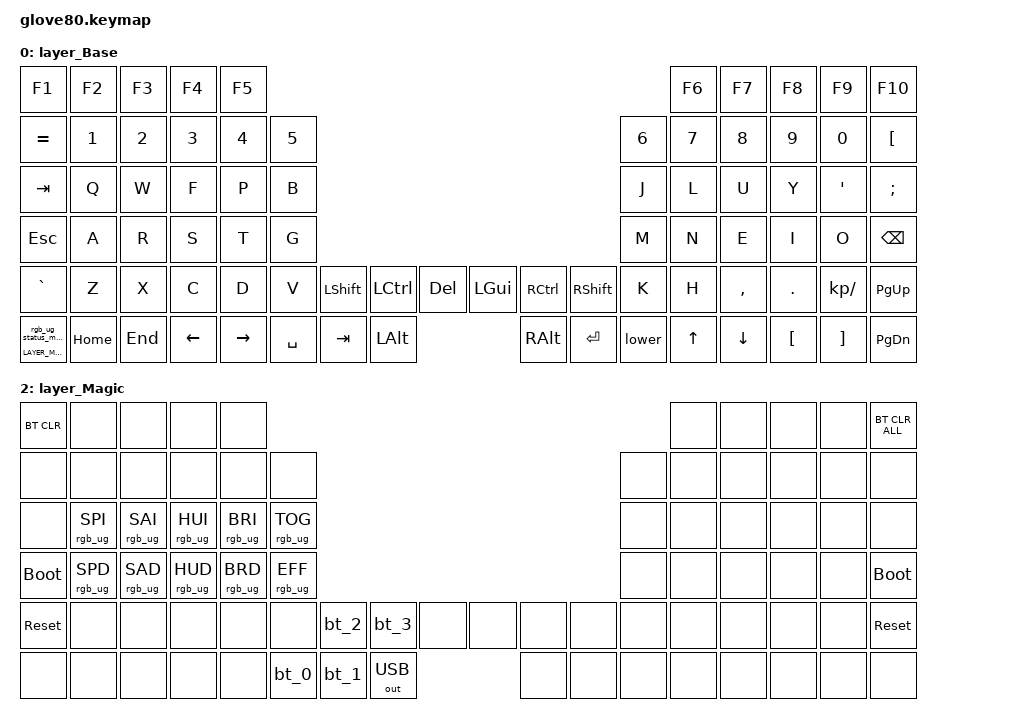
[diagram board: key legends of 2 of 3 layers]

/*
 * Copyright (c) 2020 The ZMK Contributors
 * Copyright (c) 2023 Innaworks Development Limited, trading as MoErgo
 *
 * SPDX-License-Identifier: MIT
 */


/* THIS FILE WAS GENERATED BY GLOVE80 LAYOUT EDITOR
 *
 * This file was generated automatically. You may or may not want to
 * edit it directly.
 */

#include <behaviors.dtsi>
/* Include all behavior includes needed */
#include <dt-bindings/zmk/outputs.h>
#include <dt-bindings/zmk/keys.h>
#include <dt-bindings/zmk/bt.h>
#include <dt-bindings/zmk/rgb.h>

/* Automatically generated layer name #define */
#define LAYER_Base 0
#define LAYER_Lower 1
#define LAYER_Magic 2

/* To deal with the situation where there is no Lower layer, to keep &lower happy */
#ifndef LAYER_Lower
#define LAYER_Lower 0
#endif

/* Custom Device-tree */



/* Glove80 system behavior & macros */
/ {
    behaviors {
        // For the "layer" key, it'd nice to be able to use it as either a shift or a toggle.
        // Configure it as a tap dance, so the first tap (or hold) is a &mo and the second tap is a &to
        lower: lower {
            compatible = "zmk,behavior-tap-dance";
            label = "LAYER_TAP_DANCE";
            #binding-cells = <0>;
            tapping-term-ms = <200>;
            bindings = <&mo LAYER_Lower>, <&to LAYER_Lower>;
        };
    };
};

/ {
    macros {
        rgb_ug_status_macro: rgb_ug_status_macro {
            label = "RGB_UG_STATUS";
            compatible = "zmk,behavior-macro";
            #binding-cells = <0>;
            bindings
                = <&rgb_ug RGB_STATUS>;
        };
    };
};


/ {
#ifdef BT_DISC_CMD
    behaviors {
        bt_0: bt_0 {
            compatible = "zmk,behavior-tap-dance";
            label = "BT_0";
            #binding-cells = <0>;
            tapping-term-ms = <200>;
            bindings = <&bt_select_0>, <&bt BT_DISC 0>;
        };
        bt_1: bt_1 {
            compatible = "zmk,behavior-tap-dance";
            label = "BT_1";
            #binding-cells = <0>;
            tapping-term-ms = <200>;
            bindings = <&bt_select_1>, <&bt BT_DISC 1>;
        };
        bt_2: bt_2 {
            compatible = "zmk,behavior-tap-dance";
            label = "BT_2";
            #binding-cells = <0>;
            tapping-term-ms = <200>;
            bindings = <&bt_select_2>, <&bt BT_DISC 2>;
        };
        bt_3: bt_3 {
            compatible = "zmk,behavior-tap-dance";
            label = "BT_3";
            #binding-cells = <0>;
            tapping-term-ms = <200>;
            bindings = <&bt_select_3>, <&bt BT_DISC 3>;
        };
    };
    macros {
        bt_select_0: bt_select_0 {
            label = "BT_SELECT_0";
            compatible = "zmk,behavior-macro";
            #binding-cells = <0>;
            bindings
                = <&out OUT_BLE>,
                  <&bt BT_SEL 0>;
        };
        bt_select_1: bt_select_1 {
            label = "BT_SELECT_1";
            compatible = "zmk,behavior-macro";
            #binding-cells = <0>;
            bindings
                = <&out OUT_BLE>,
                  <&bt BT_SEL 1>;
        };
        bt_select_2: bt_select_2 {
            label = "BT_SELECT_2";
            compatible = "zmk,behavior-macro";
            #binding-cells = <0>;
            bindings
                = <&out OUT_BLE>,
                  <&bt BT_SEL 2>;
        };
        bt_select_3: bt_select_3 {
            label = "BT_SELECT_3";
            compatible = "zmk,behavior-macro";
            #binding-cells = <0>;
            bindings
                = <&out OUT_BLE>,
                  <&bt BT_SEL 3>;
        };
    };
#else
    macros {
        bt_0: bt_0 {
            label = "BT_0";
            compatible = "zmk,behavior-macro";
            #binding-cells = <0>;
            bindings
                = <&out OUT_BLE>,
                  <&bt BT_SEL 0>;
        };
        bt_1: bt_1 {
            label = "BT_1";
            compatible = "zmk,behavior-macro";
            #binding-cells = <0>;
            bindings
                = <&out OUT_BLE>,
                  <&bt BT_SEL 1>;
        };
        bt_2: bt_2 {
            label = "BT_2";
            compatible = "zmk,behavior-macro";
            #binding-cells = <0>;
            bindings
                = <&out OUT_BLE>,
                  <&bt BT_SEL 2>;
        };
        bt_3: bt_3 {
            label = "BT_3";
            compatible = "zmk,behavior-macro";
            #binding-cells = <0>;
            bindings
                = <&out OUT_BLE>,
                  <&bt BT_SEL 3>;
        };
    };
#endif
};

/ {
    behaviors {
        magic: magic {
            compatible = "zmk,behavior-hold-tap";
            label = "MAGIC_HOLD_TAP";
            #binding-cells = <2>;
            flavor = "tap-preferred";
            tapping-term-ms = <200>;
            bindings = <&mo>, <&rgb_ug_status_macro>;
        };
    };
};

/* #define for key positions */
#define POS_LH_T1 52
#define POS_LH_T2 53
#define POS_LH_T3 54
#define POS_LH_T4 69
#define POS_LH_T5 70
#define POS_LH_T6 71
#define POS_LH_C1R2 15
#define POS_LH_C1R3 27
#define POS_LH_C1R4 39
#define POS_LH_C1R5 51
#define POS_LH_C2R1 4
#define POS_LH_C2R2 14
#define POS_LH_C2R3 26
#define POS_LH_C2R4 38
#define POS_LH_C2R5 50
#define POS_LH_C2R6 68
#define POS_LH_C3R1 3
#define POS_LH_C3R2 13
#define POS_LH_C3R3 25
#define POS_LH_C3R4 37
#define POS_LH_C3R5 49
#define POS_LH_C3R6 67
#define POS_LH_C4R1 2
#define POS_LH_C4R2 12
#define POS_LH_C4R3 24
#define POS_LH_C4R4 36
#define POS_LH_C4R5 48
#define POS_LH_C4R6 66
#define POS_LH_C5R1 1
#define POS_LH_C5R2 11
#define POS_LH_C5R3 23
#define POS_LH_C5R4 35
#define POS_LH_C5R5 47
#define POS_LH_C5R6 65
#define POS_LH_C6R1 0
#define POS_LH_C6R2 10
#define POS_LH_C6R3 22
#define POS_LH_C6R4 34
#define POS_LH_C6R5 46
#define POS_LH_C6R6 64
#define POS_RH_T1 57
#define POS_RH_T2 56
#define POS_RH_T3 55
#define POS_RH_T4 74
#define POS_RH_T5 73
#define POS_RH_T6 72
#define POS_RH_C1R2 16
#define POS_RH_C1R3 28
#define POS_RH_C1R4 40
#define POS_RH_C1R5 58
#define POS_RH_C2R1 5
#define POS_RH_C2R2 17
#define POS_RH_C2R3 29
#define POS_RH_C2R4 41
#define POS_RH_C2R5 59
#define POS_RH_C2R6 75
#define POS_RH_C3R1 6
#define POS_RH_C3R2 18
#define POS_RH_C3R3 30
#define POS_RH_C3R4 42
#define POS_RH_C3R5 60
#define POS_RH_C3R6 76
#define POS_RH_C4R1 7
#define POS_RH_C4R2 19
#define POS_RH_C4R3 31
#define POS_RH_C4R4 43
#define POS_RH_C4R5 61
#define POS_RH_C4R6 77
#define POS_RH_C5R1 8
#define POS_RH_C5R2 20
#define POS_RH_C5R3 32
#define POS_RH_C5R4 44
#define POS_RH_C5R5 62
#define POS_RH_C5R6 78
#define POS_RH_C6R1 9
#define POS_RH_C6R2 21
#define POS_RH_C6R3 33
#define POS_RH_C6R4 45
#define POS_RH_C6R5 63
#define POS_RH_C6R6 79


/* Special characters accessed with Shift */
#define SW_EXCL &kp LS(N1)          // Maps to `!` on Swedish layout (Shift + 1)
#define SW_AT &kp LS(N2)            // Maps to `@` on Swedish layout (Shift + 2)
#define SW_HASH &kp LS(N3)          // Maps to `#` on Swedish layout (Shift + 3)
#define SW_DOLLAR &kp LS(N4)        // Maps to `$` on Swedish layout (Shift + 4)
#define SW_PERCENT &kp LS(N5)       // Maps to `%` on Swedish layout (Shift + 5)
#define SW_AMPERSAND &kp LS(N6)     // Maps to `&` on Swedish layout (Shift + 6)
#define SW_SLASH &kp LS(N7)         // Maps to `/` on Swedish layout (Shift + 7)
#define SW_LPAREN &kp LS(N8)        // Maps to `(` on Swedish layout (Shift + 8)
#define SW_RPAREN &kp LS(N9)        // Maps to `)` on Swedish layout (Shift + 9)
#define SW_EQUAL &kp LS(N0)         // Maps to `=` on Swedish layout (Shift + 0)
#define SW_QUESTION &kp LS(MINUS)   // Maps to `?` on Swedish layout (Shift + `-`)
#define SW_GRAVE &kp LS(GRAVE)      // Maps to `~` on Swedish layout (Shift + `´`)
#define SW_ASTERISK &kp LS(BSLH)    // Maps to `*` on Swedish layout (Shift + `\`)
#define SW_PLUS &kp EQUAL           // Maps to `+` on Swedish layout (`+` key)
#define SW_UNDERSCORE &kp LS(KP_MINUS) // Maps to `_` on Swedish layout (Shift + `KP_MINUS`)

/* Special characters accessed with AltGr */
#define SW_PIPE &kp RA(MINUS)       // Maps to `|` on Swedish layout (AltGr + `-`)
#define SW_TILDE &kp RA(GRAVE)      // Maps to `~` on Swedish layout (AltGr + `´`)
#define SW_BACKSLASH &kp RA(LBRKT)  // Maps to `\` on Swedish layout (AltGr + `[` )
#define SW_LBRACKET &kp RA(8)       // Maps to `[` on Swedish layout (AltGr + `8`)
#define SW_RBRACKET &kp RA(9)       // Maps to `]` on Swedish layout (AltGr + `9`)
#define SW_CURRENCY &kp RA(4)       // Maps to `¤` on Swedish layout (AltGr + `4`)
#define SW_EURO &kp RA(5)           // Maps to `€` on Swedish layout (AltGr + `5`)
#define SW_BRACE_LEFT &kp RA(7)     // Maps to `{` on Swedish layout (AltGr + `7`)
#define SW_BRACE_RIGHT &kp RA(0)    // Maps to `}` on Swedish layout (AltGr + `0`)
#define SW_AT_SIGN &kp RA(N2)       // Maps to `@` on Swedish layout (AltGr + `2`)
#define SW_HASH_SIGN &kp RA(N3)     // Maps to `#` on Swedish layout (AltGr + `3`)
#define SW_POUND &kp RA(N3)         // Maps to `£` on Swedish layout (AltGr + `3`)
#define SW_SECTION &kp RA(N4)       // Maps to `§` on Swedish layout (AltGr + `4`)

/* Miscellaneous */
#define SW_SEMICOLON &kp SQT        // Maps to `;` on Swedish layout
#define SW_COLON &kp LS(DOT)        // Maps to `:` on Swedish layout (Shift + `.``)
#define SW_LT &kp COMMA             // Maps to `<` on Swedish layout
#define SW_GT &kp LS(COMMA)         // Maps to `>` on Swedish layout (Shift + `,`)
#define SW_QUOTE &kp LS(SQT)        // Maps to `"` on Swedish layout (Shift + `´`)
#define SW_DOLLAR_SIGN &kp LS(4)    // Maps to `$` on Swedish layout (Shift + `4`)
#define SW_AMP_SIGN &kp LS(6)       // Maps to `&` on Swedish layout (Shift + `6`)

#define SW_CIRCUMFLEX &kp LS(GRAVE) // Maps to `^` (Shift + `^`)

/* Custom Defined Behaviors */
/ {

};

/* Automatically generated macro definitions */
/ {
    macros {
        directoryUp: directoryUp {
            label = "&DIRECTORYUP";
            compatible = "zmk,behavior-macro";
            #binding-cells = <0>;
            
            
            bindings
                = <&kp DOT>
                , <&kp DOT>
                , <&kp KP_SLASH>;
        };
    backslash: backslash {
            label = "&BACKSLASH";
            compatible = "zmk,behavior-macro";
            #binding-cells = <0>;
            
            
            bindings
                = <&sk RALT>
                , <&kp MINUS>;
        };
    star: star {
            label = "&STAR";
            compatible = "zmk,behavior-macro";
            #binding-cells = <0>;
            
            
            bindings
                = <&sk LSHFT>
                , <&kp BSLH>;
        };
    slash: slash {
            label = "&SLASH";
            compatible = "zmk,behavior-macro";
            #binding-cells = <0>;
            
            
            bindings
                = <&sk LSHFT>
                , <&kp N7>;
        };
    caret: caret {
            label = "&CARET";
            compatible = "zmk,behavior-macro";
            #binding-cells = <0>;
            
            
            bindings
                = <&sk LSHFT>
                , <&kp RBKT>;
        };
    hash: hash {
            label = "&HASH";
            compatible = "zmk,behavior-macro";
            #binding-cells = <0>;
            
            
            bindings
                = <&sk LSHFT>
                , <&kp N3>;
        };
    equal: equal {
            label = "&EQUAL";
            compatible = "zmk,behavior-macro";
            #binding-cells = <0>;
            
            
            bindings
                = <&sk LSHFT>
                , <&kp N0>;
        };
    exclamation: exclamation {
            label = "&EXCLAMATION";
            compatible = "zmk,behavior-macro";
            #binding-cells = <0>;
            
            
            bindings
                = <&sk LSHFT>
                , <&kp N1>;
        };
    quote: quote {
            label = "&QUOTE";
            compatible = "zmk,behavior-macro";
            #binding-cells = <0>;
            
            
            bindings
                = <&sk LSHFT>
                , <&kp N2>;
        };
    morehthan: morehthan {
            label = "&MOREHTHAN";
            compatible = "zmk,behavior-macro";
            #binding-cells = <0>;
            
            
            bindings
                = <&sk LSHFT>
                , <&kp NON_US_BSLH>;
        };
    tilde: tilde {
            label = "&TILDE";
            compatible = "zmk,behavior-macro";
            #binding-cells = <0>;
            
            
            bindings
                = <&sk RALT>
                , <&kp RBKT>;
        };
    dollar: dollar {
            label = "&DOLLAR";
            compatible = "zmk,behavior-macro";
            #binding-cells = <0>;
            
            
            bindings
                = <&sk RALT>
                , <&kp N4>;
        };
    leftbraces: leftbraces {
            label = "&LEFTBRACES";
            compatible = "zmk,behavior-macro";
            #binding-cells = <0>;
            
            
            bindings
                = <&sk RALT>
                , <&kp N7>;
        };
    rightbraces: rightbraces {
            label = "&RIGHTBRACES";
            compatible = "zmk,behavior-macro";
            #binding-cells = <0>;
            
            
            bindings
                = <&sk RALT>
                , <&kp N0>;
        };
    rightbrackets: rightbrackets {
            label = "&RIGHTBRACKETS";
            compatible = "zmk,behavior-macro";
            #binding-cells = <0>;
            
            
            bindings
                = <&sk RALT>
                , <&kp N9>;
        };
    leftbrackets: leftbrackets {
            label = "&LEFTBRACKETS";
            compatible = "zmk,behavior-macro";
            #binding-cells = <0>;
            
            
            bindings
                = <&sk RALT>
                , <&kp N8>;
        };
    leftparentheses: leftparentheses {
            label = "&LEFTPARENTHESES";
            compatible = "zmk,behavior-macro";
            #binding-cells = <0>;
            
            
            bindings
                = <&sk LSHFT>
                , <&kp N8>;
        };
    rightparentheses: rightparentheses {
            label = "&RIGHTPARENTHESES";
            compatible = "zmk,behavior-macro";
            #binding-cells = <0>;
            
            
            bindings
                = <&sk LSHFT>
                , <&kp N9>;
        };
    pipe: pipe {
            label = "&PIPE";
            compatible = "zmk,behavior-macro";
            #binding-cells = <0>;
            
            
            bindings
                = <&sk RALT>
                , <&kp NON_US_BSLH>;
        };
    and: and {
            label = "&AND";
            compatible = "zmk,behavior-macro";
            #binding-cells = <0>;
            
            
            bindings
                = <&sk LSHFT>
                , <&kp N6>;
        };
    colon: colon {
            label = "&COLON";
            compatible = "zmk,behavior-macro";
            #binding-cells = <0>;
            
            
            bindings
                = <&sk LSHFT>
                , <&kp DOT>;
        };
    at: at {
            label = "&AT";
            compatible = "zmk,behavior-macro";
            #binding-cells = <0>;
            
            
            bindings
                = <&sk RALT>
                , <&kp N2>;
        };
    questionmark: questionmark {
            label = "&QUESTIONMARK";
            compatible = "zmk,behavior-macro";
            #binding-cells = <0>;
            
            
            bindings
                = <&sk LSHFT>
                , <&kp MINUS>;
        };
    percent: percent {
            label = "&PERCENT";
            compatible = "zmk,behavior-macro";
            #binding-cells = <0>;
            
            
            bindings
                = <&sk LSHFT>
                , <&kp N5>;
        };
    };
};

/* Automatically generated combos definitions */
/ {
    combos {
            compatible = "zmk,combos";
    };
};

/* Automatically generated keymap */
/ {
    keymap {
        compatible = "zmk,keymap";


        layer_Base {
            bindings = <
               &kp F1    &kp F2   &kp F3    &kp F4     &kp F5                                                                                  &kp F6     &kp F7    &kp F8        &kp F9    &kp F10
            &kp EQUAL    &kp N1   &kp N2    &kp N3     &kp N4  &kp N5                                                                  &kp N6  &kp N7     &kp N8    &kp N9        &kp N0   &kp LBKT
              &kp TAB     &kp Q    &kp W     &kp F      &kp P   &kp B                                                                   &kp J   &kp L      &kp U     &kp Y       &kp SQT   &kp SEMI
              &kp ESC     &kp A    &kp R     &kp S      &kp T   &kp G                                                                   &kp M   &kp N      &kp E     &kp I         &kp O   &kp BSPC
            &kp GRAVE     &kp Z    &kp X     &kp C      &kp D   &kp V  &kp LSHFT  &kp LCTRL   &kp DEL  &kp LGUI  &kp RCTRL  &kp RSHFT   &kp K   &kp H  &kp COMMA   &kp DOT  &kp KP_SLASH  &kp PG_UP
 &magic LAYER_Magic 0  &kp HOME  &kp END  &kp LEFT  &kp RIGHT          &kp SPACE    &kp TAB  &kp LALT  &kp RALT    &kp RET     &lower          &kp UP   &kp DOWN  &kp LBKT      &kp RBKT  &kp PG_DN
            >;
        };

        layer_Lower {
    bindings = <
        &trans    &trans      &trans        &trans         &trans                                                                                          &trans            &trans         &trans             &trans  &trans,
        &trans    &none     &kp INS      &kp CAPS         &none         &none                                                  &none                &none             &none          &none              &none  &trans,
        &trans    &less_than  &more_than &leftparentheses  &rightparentheses  &backslash    &star    &exclamation    &equal  &plus   &percent   &trans,
        &trans    &leftbrackets  &rightbrackets  &leftbraces  &rightbraces  &pipe    &hash    &quote  &kp SQT   &colon  &trans,
        &trans    &caret   &dollar     &kp MINUS  &underscore   &none  &trans  &trans   &to 0  &trans  &trans  &trans  &kp COMMA   &and   &at       &tilde  &questionmark  &trans,
        &magic LAYER_Magic 0  &trans    &trans        &trans         &trans                &trans  &trans  &trans  &trans  &trans  &trans    &trans  &trans     &kp KP_DOT       &kp KP_ENTER  &trans
    >;
};


        layer_Magic {
            bindings = <
  &bt BT_CLR            &none            &none            &none            &none                                                                                  &none   &none   &none   &none  &bt BT_CLR_ALL
       &none            &none            &none            &none            &none            &none                                                         &none   &none   &none   &none   &none           &none
       &none  &rgb_ug RGB_SPI  &rgb_ug RGB_SAI  &rgb_ug RGB_HUI  &rgb_ug RGB_BRI  &rgb_ug RGB_TOG                                                         &none   &none   &none   &none   &none           &none
 &bootloader  &rgb_ug RGB_SPD  &rgb_ug RGB_SAD  &rgb_ug RGB_HUD  &rgb_ug RGB_BRD  &rgb_ug RGB_EFF                                                         &none   &none   &none   &none   &none     &bootloader
  &sys_reset            &none            &none            &none            &none            &none   &bt_2   &bt_3         &none   &none   &none   &none   &none   &none   &none   &none   &none      &sys_reset
       &none            &none            &none            &none            &none                    &bt_0   &bt_1  &out OUT_USB   &none   &none   &none           &none   &none   &none   &none           &none
            >;
        };

    };
};
